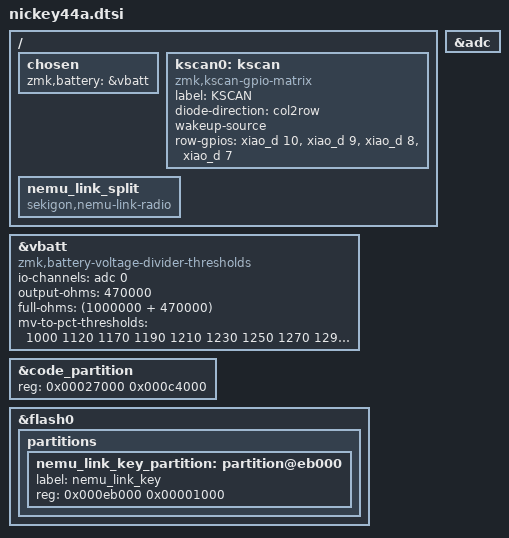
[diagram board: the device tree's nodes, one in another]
#include "nickey44a_layouts.dtsi"

/ {
    chosen {
        zmk,battery = &vbatt;
    };

    kscan0: kscan {
        compatible = "zmk,kscan-gpio-matrix";
        label = "KSCAN";
        diode-direction = "col2row";
        wakeup-source;
            row-gpios
                = <&xiao_d 10 (GPIO_ACTIVE_HIGH | GPIO_PULL_DOWN)>
                , <&xiao_d 9 (GPIO_ACTIVE_HIGH | GPIO_PULL_DOWN)>
                , <&xiao_d 8 (GPIO_ACTIVE_HIGH | GPIO_PULL_DOWN)>
                , <&xiao_d 7 (GPIO_ACTIVE_HIGH | GPIO_PULL_DOWN)>
                ;
    };
};

&adc {
    status = "okay";
};

&vbatt {
    compatible = "zmk,battery-voltage-divider-thresholds";
    io-channels = <&adc 0>;
    /delete-property/ power-gpios;
    output-ohms = <470000>;
    full-ohms = <(1000000 + 470000)>;
    // Ni-MH向けにチューニング
    mv-to-pct-thresholds = <1000 1120 1170 1190 1210 1230 1250 1270 1290 1330 1400>;
};

/* nemu-link: 2.4GHz radio shared by both halves and the dongle. */
/ {
    nemu_link_split {
        compatible = "sekigon,nemu-link-radio";
    };
};

/*
 * nemu-link key storage: last 4 KiB of the XIAO BLE application flash
 * (UF2 SD v7 layout: code 0x27000..0xebfff -> 0x27000..0xeafff + key 0xeb000).
 */
&code_partition {
    reg = <0x00027000 0x000c4000>;
};

&flash0 {
    partitions {
        nemu_link_key_partition: partition@eb000 {
            label = "nemu_link_key";
            reg = <0x000eb000 0x00001000>;
        };
    };
};
